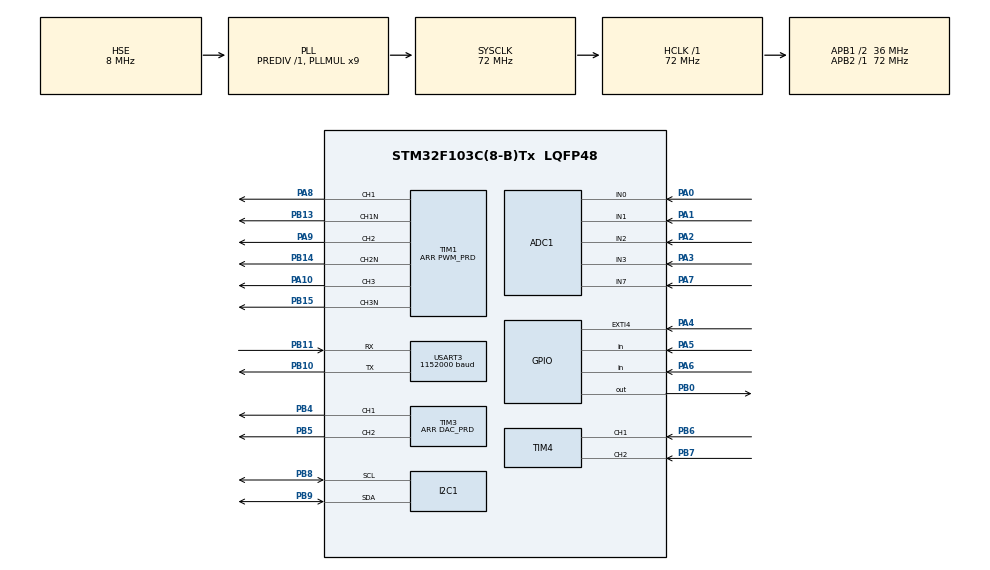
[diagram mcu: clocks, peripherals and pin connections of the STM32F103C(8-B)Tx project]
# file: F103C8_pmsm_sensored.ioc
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ADC1.Channel-10\#ChannelInjectedConversion=ADC_CHANNEL_3
ADC1.Channel-11\#ChannelInjectedConversion=ADC_CHANNEL_0
ADC1.Channel-12\#ChannelRegularConversion=ADC_CHANNEL_7
ADC1.Channel-8\#ChannelInjectedConversion=ADC_CHANNEL_1
ADC1.Channel-9\#ChannelInjectedConversion=ADC_CHANNEL_2
ADC1.ContinuousConvMode=DISABLE
ADC1.DataAlign=ADC_DATAALIGN_RIGHT
ADC1.DiscontinuousConvMode=DISABLE
ADC1.EnableAnalogWatchDog=false
ADC1.EnableRegularConversion=ENABLE
ADC1.ExternalTrigInjecConv=ADC_EXTERNALTRIGINJECCONV_T1_CC4
ADC1.InjNumberOfConversion=4
ADC1.InjectedConvMode=None
ADC1.InjectedOffset-10\#ChannelInjectedConversion=0
ADC1.InjectedOffset-11\#ChannelInjectedConversion=0
ADC1.InjectedOffset-8\#ChannelInjectedConversion=0
ADC1.InjectedOffset-9\#ChannelInjectedConversion=0
ADC1.NbrOfConversionFlag=1
ADC1.Rank-10\#ChannelInjectedConversion=3
ADC1.Rank-11\#ChannelInjectedConversion=4
ADC1.Rank-12\#ChannelRegularConversion=1
ADC1.Rank-8\#ChannelInjectedConversion=1
ADC1.Rank-9\#ChannelInjectedConversion=2
ADC1.SamplingTime-10\#ChannelInjectedConversion=ADC_SAMPLETIME_1CYCLE_5
ADC1.SamplingTime-11\#ChannelInjectedConversion=ADC_SAMPLETIME_1CYCLE_5
ADC1.SamplingTime-12\#ChannelRegularConversion=ADC_SAMPLETIME_1CYCLE_5
ADC1.SamplingTime-8\#ChannelInjectedConversion=ADC_SAMPLETIME_1CYCLE_5
ADC1.SamplingTime-9\#ChannelInjectedConversion=ADC_SAMPLETIME_1CYCLE_5
ADC1.ScanConvMode=ADC_SCAN_ENABLE
ADC1.master=1
Dma.ADC1.0.Direction=DMA_PERIPH_TO_MEMORY
Dma.ADC1.0.Instance=DMA1_Channel1
Dma.ADC1.0.MemDataAlignment=DMA_MDATAALIGN_WORD
Dma.ADC1.0.MemInc=DMA_MINC_ENABLE
Dma.ADC1.0.Mode=DMA_CIRCULAR
Dma.ADC1.0.PeriphDataAlignment=DMA_PDATAALIGN_WORD
Dma.ADC1.0.PeriphInc=DMA_PINC_DISABLE
Dma.ADC1.0.Priority=DMA_PRIORITY_LOW
Dma.Request0=ADC1
Dma.Request1=USART3_RX
Dma.Request2=USART3_TX
Dma.USART3_RX.1.Direction=DMA_PERIPH_TO_MEMORY
Dma.USART3_RX.1.Instance=DMA1_Channel3
Dma.USART3_RX.1.MemDataAlignment=DMA_MDATAALIGN_BYTE
Dma.USART3_RX.1.MemInc=DMA_MINC_ENABLE
Dma.USART3_RX.1.Mode=DMA_NORMAL
Dma.USART3_RX.1.PeriphDataAlignment=DMA_PDATAALIGN_BYTE
Dma.USART3_RX.1.PeriphInc=DMA_PINC_DISABLE
Dma.USART3_RX.1.Priority=DMA_PRIORITY_LOW
Dma.USART3_TX.2.Direction=DMA_MEMORY_TO_PERIPH
Dma.USART3_TX.2.Instance=DMA1_Channel2
Dma.USART3_TX.2.MemDataAlignment=DMA_MDATAALIGN_BYTE
Dma.USART3_TX.2.MemInc=DMA_MINC_ENABLE
Dma.USART3_TX.2.Mode=DMA_NORMAL
Dma.USART3_TX.2.PeriphDataAlignment=DMA_PDATAALIGN_BYTE
Dma.USART3_TX.2.PeriphInc=DMA_PINC_DISABLE
Dma.USART3_TX.2.Priority=DMA_PRIORITY_LOW
Mcu.Family=STM32F1
Mcu.Name=STM32F103C(8-B)Tx
Mcu.Package=LQFP48
Mcu.UserConstants=PWM_PRD,72000000/pwmFreq/2;DAC_PRD,1024;pwmFreq,10000;Uart3BaudRate,1152000
NVIC.ADC1_2_IRQn=true\:0\:0\:false\:false\:true
NVIC.DMA1_Channel1_IRQn=true\:0\:0\:false\:false\:true
NVIC.DMA1_Channel2_IRQn=true\:0\:0\:false\:false\:true
NVIC.DMA1_Channel3_IRQn=true\:0\:0\:false\:false\:true
NVIC.EXTI4_IRQn=true\:0\:0\:false\:false\:true
NVIC.PriorityGroup=NVIC_PRIORITYGROUP_4
NVIC.TIM1_CC_IRQn=true\:0\:0\:false\:false\:true
NVIC.TIM1_UP_IRQn=true\:1\:0\:true\:false\:true
NVIC.TIM3_IRQn=true\:0\:0\:false\:false\:true
NVIC.USART3_IRQn=true\:0\:0\:false\:false\:true
PA0-WKUP.Signal=ADCx_IN0
PA1.Signal=ADCx_IN1
PA10.Signal=S_TIM1_CH3
PA13.Mode=Serial_Wire
PA13.Signal=SYS_JTMS-SWDIO
PA14.Mode=Serial_Wire
PA14.Signal=SYS_JTCK-SWCLK
PA2.Signal=ADCx_IN2
PA3.Signal=ADCx_IN3
PA4.GPIO_ModeDefaultEXTI=GPIO_MODE_IT_RISING_FALLING
PA4.GPIO_PuPd=GPIO_PULLUP
PA4.Signal=GPXTI4
PA5.GPIO_PuPd=GPIO_PULLUP
PA5.Signal=GPIO_Input
PA6.GPIO_PuPd=GPIO_PULLUP
PA6.Signal=GPIO_Input
PA7.Signal=ADCx_IN7
PA8.Signal=S_TIM1_CH1
PA9.Signal=S_TIM1_CH2
PB0.Signal=GPIO_Output
PB10.Mode=Asynchronous
PB10.Signal=USART3_TX
PB11.Mode=Asynchronous
PB11.Signal=USART3_RX
PB13.Mode=PWM Generation1 CH1 CH1N
PB13.Signal=TIM1_CH1N
PB14.Mode=PWM Generation2 CH2 CH2N
PB14.Signal=TIM1_CH2N
PB15.Mode=PWM Generation3 CH3 CH3N
PB15.Signal=TIM1_CH3N
PB4.Signal=S_TIM3_CH1
PB5.Signal=S_TIM3_CH2
PB6.GPIO_PuPd=GPIO_PULLUP
PB6.Signal=S_TIM4_CH1
PB7.GPIO_PuPd=GPIO_PULLUP
PB7.Signal=S_TIM4_CH2
PB8.Mode=I2C
PB8.Signal=I2C1_SCL
PB9.Mode=I2C
PB9.Signal=I2C1_SDA
PC14-OSC32_IN.Mode=LSE-External-Oscillator
PC14-OSC32_IN.Signal=RCC_OSC32_IN
PC15-OSC32_OUT.Mode=LSE-External-Oscillator
PC15-OSC32_OUT.Signal=RCC_OSC32_OUT
PD0-OSC_IN.Mode=HSE-External-Oscillator
PD0-OSC_IN.Signal=RCC_OSC_IN
PD1-OSC_OUT.Mode=HSE-External-Oscillator
PD1-OSC_OUT.Signal=RCC_OSC_OUT
ProjectManager.HeapSize=0x200
ProjectManager.StackSize=0x400
ProjectManager.TargetToolchain=SW4STM32
RCC.ADCPresc=RCC_ADCPCLK2_DIV6
RCC.AHBFreq_Value=72000000
RCC.APB1CLKDivider=RCC_HCLK_DIV2
RCC.APB1Freq_Value=36000000
RCC.APB1TimFreq_Value=72000000
RCC.APB2Freq_Value=72000000
RCC.APB2TimFreq_Value=72000000
RCC.HCLKFreq_Value=72000000
RCC.PLLMUL=RCC_PLL_MUL9
RCC.PLLSourceVirtual=RCC_PLLSOURCE_HSE
RCC.SYSCLKFreq_VALUE=72000000
RCC.SYSCLKSource=RCC_SYSCLKSOURCE_PLLCLK
RCC.USBFreq_Value=48000000
RCC.USBPrescaler=RCC_USBCLKSOURCE_PLL_DIV1_5
SH.ADCx_IN0.0=ADC1_IN0,IN0
SH.ADCx_IN1.0=ADC1_IN1,IN1
SH.ADCx_IN2.0=ADC1_IN2,IN2
SH.ADCx_IN3.0=ADC1_IN3,IN3
SH.ADCx_IN7.0=ADC1_IN7,IN7
SH.S_TIM1_CH1.0=TIM1_CH1,PWM Generation1 CH1 CH1N
SH.S_TIM1_CH2.0=TIM1_CH2,PWM Generation2 CH2 CH2N
SH.S_TIM1_CH3.0=TIM1_CH3,PWM Generation3 CH3 CH3N
SH.S_TIM3_CH1.0=TIM3_CH1,PWM Generation1 CH1
SH.S_TIM3_CH2.0=TIM3_CH2,PWM Generation2 CH2
SH.S_TIM4_CH1.0=TIM4_CH1,Encoder_Interface
SH.S_TIM4_CH2.0=TIM4_CH2,Encoder_Interface
TIM1.AutomaticOutput=TIM_AUTOMATICOUTPUT_DISABLE
TIM1.BreakState=TIM_BREAK_DISABLE
TIM1.Channel-PWM\ Generation1\ CH1\ CH1N=TIM_CHANNEL_1
TIM1.Channel-PWM\ Generation2\ CH2\ CH2N=TIM_CHANNEL_2
TIM1.Channel-PWM\ Generation3\ CH3\ CH3N=TIM_CHANNEL_3
TIM1.Channel-PWM\ Generation4\ No\ Output=TIM_CHANNEL_4
TIM1.ClockDivision=TIM_CLOCKDIVISION_DIV1
TIM1.CounterMode=TIM_COUNTERMODE_CENTERALIGNED1
TIM1.DeadTime=50
TIM1.LockLevel=TIM_LOCKLEVEL_OFF
TIM1.OCFastMode_PWM-PWM\ Generation1\ CH1\ CH1N=TIM_OCFAST_ENABLE
TIM1.OCFastMode_PWM-PWM\ Generation2\ CH2\ CH2N=TIM_OCFAST_ENABLE
TIM1.OCFastMode_PWM-PWM\ Generation3\ CH3\ CH3N=TIM_OCFAST_ENABLE
TIM1.OCFastMode_PWM-PWM\ Generation4\ No\ Output=TIM_OCFAST_ENABLE
TIM1.OCMode_PWM-PWM\ Generation1\ CH1\ CH1N=TIM_OCMODE_PWM2
TIM1.OCMode_PWM-PWM\ Generation2\ CH2\ CH2N=TIM_OCMODE_PWM2
TIM1.OCMode_PWM-PWM\ Generation3\ CH3\ CH3N=TIM_OCMODE_PWM2
TIM1.OCMode_PWM-PWM\ Generation4\ No\ Output=TIM_OCMODE_PWM1
TIM1.OffStateIDLEMode=TIM_OSSI_DISABLE
TIM1.OffStateRunMode=TIM_OSSR_ENABLE
TIM1.Period=PWM_PRD
TIM1.Pulse-PWM\ Generation1\ CH1\ CH1N=0
TIM1.Pulse-PWM\ Generation2\ CH2\ CH2N=0
TIM1.Pulse-PWM\ Generation3\ CH3\ CH3N=0
TIM1.RepetitionCounter=1
TIM1.TIM_MasterOutputTrigger=TIM_TRGO_ENABLE
TIM1.TIM_MasterSlaveMode=TIM_MASTERSLAVEMODE_DISABLE
TIM3.Channel-PWM\ Generation1\ CH1=TIM_CHANNEL_1
TIM3.Channel-PWM\ Generation2\ CH2=TIM_CHANNEL_2
TIM3.OCFastMode_PWM-PWM\ Generation1\ CH1=TIM_OCFAST_ENABLE
TIM3.OCFastMode_PWM-PWM\ Generation2\ CH2=TIM_OCFAST_ENABLE
TIM3.Period=DAC_PRD
TIM4.EncoderMode=TIM_ENCODERMODE_TI12
TIM4.IC1Filter=5
TIM4.IC2Filter=5
USART3.BaudRate=1152000
USART3.VirtualMode=VM_ASYNC
VP_TIM1_VS_ClockSourceINT.Mode=Internal
VP_TIM1_VS_no_output4.Mode=PWM Generation4 No Output
VP_TIM3_VS_ClockSourceINT.Mode=Internal
board=F103C8_pmsm_sensored

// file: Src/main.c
/**
  ******************************************************************************
  * File Name          : main.c
  * Description        : Main program body
  ******************************************************************************
  ** This notice applies to any and all portions of this file
  * that are not between comment pairs USER CODE BEGIN and
  * USER CODE END. Other portions of this file, whether
  * inserted by the user or by software development tools
  * are owned by their respective copyright owners.
  *
  * COPYRIGHT(c) 2017 STMicroelectronics
  *
  * Redistribution and use in source and binary forms, with or without modification,
  * are permitted provided that the following conditions are met:
  *   1. Redistributions of source code must retain the above copyright notice,
  *      this list of conditions and the following disclaimer.
  *   2. Redistributions in binary form must reproduce the above copyright notice,
  *      this list of conditions and the following disclaimer in the documentation
  *      and/or other materials provided with the distribution.
  *   3. Neither the name of STMicroelectronics nor the names of its contributors
  *      may be used to endorse or promote products derived from this software
  *      without specific prior written permission.
  *
  * THIS SOFTWARE IS PROVIDED BY THE COPYRIGHT HOLDERS AND CONTRIBUTORS "AS IS"
  * AND ANY EXPRESS OR IMPLIED WARRANTIES, INCLUDING, BUT NOT LIMITED TO, THE
  * IMPLIED WARRANTIES OF MERCHANTABILITY AND FITNESS FOR A PARTICULAR PURPOSE ARE
  * DISCLAIMED. IN NO EVENT SHALL THE COPYRIGHT HOLDER OR CONTRIBUTORS BE LIABLE
  * FOR ANY DIRECT, INDIRECT, INCIDENTAL, SPECIAL, EXEMPLARY, OR CONSEQUENTIAL
  * DAMAGES (INCLUDING, BUT NOT LIMITED TO, PROCUREMENT OF SUBSTITUTE GOODS OR
  * SERVICES; LOSS OF USE, DATA, OR PROFITS; OR BUSINESS INTERRUPTION) HOWEVER
  * CAUSED AND ON ANY THEORY OF LIABILITY, WHETHER IN CONTRACT, STRICT LIABILITY,
  * OR TORT (INCLUDING NEGLIGENCE OR OTHERWISE) ARISING IN ANY WAY OUT OF THE USE
  * OF THIS SOFTWARE, EVEN IF ADVISED OF THE POSSIBILITY OF SUCH DAMAGE.
  *
  ******************************************************************************
  */
#include "main.h"
#include "stm32f1xx_hal.h"

/* USER CODE BEGIN Includes */
#include "mainmain.h"
/* USER CODE END Includes */

ADC_HandleTypeDef hadc1;
DMA_HandleTypeDef hdma_adc1;

I2C_HandleTypeDef hi2c1;

TIM_HandleTypeDef htim1;
TIM_HandleTypeDef htim3;
TIM_HandleTypeDef htim4;

UART_HandleTypeDef huart3;
DMA_HandleTypeDef hdma_usart3_rx;
DMA_HandleTypeDef hdma_usart3_tx;

/* USER CODE BEGIN PV */
/* Private variables ---------------------------------------------------------*/

/* USER CODE END PV */

void SystemClock_Config(void);
static void MX_GPIO_Init(void);
static void MX_DMA_Init(void);
static void MX_TIM1_Init(void);
static void MX_ADC1_Init(void);
static void MX_TIM3_Init(void);
static void MX_TIM4_Init(void);
static void MX_USART3_UART_Init(void);
static void MX_I2C1_Init(void);

void HAL_TIM_MspPostInit(TIM_HandleTypeDef *htim);

/* USER CODE BEGIN PFP */
/* Private function prototypes -----------------------------------------------*/

/* USER CODE END PFP */

int main(void)
{

  /* MCU Configuration----------------------------------------------------------*/

  /* Reset of all peripherals, Initializes the Flash interface and the Systick. */
  HAL_Init();

  /* Configure the system clock */
  SystemClock_Config();

  /* Initialize all configured peripherals */
  MX_GPIO_Init();
  MX_DMA_Init();
  MX_TIM1_Init();
  MX_ADC1_Init();
  MX_TIM3_Init();
  MX_TIM4_Init();
  MX_USART3_UART_Init();
  MX_I2C1_Init();

  /* USER CODE BEGIN 2 */
	userinit();
  /* USER CODE END 2 */

  /* Infinite loop */
	while (1)
	{

  /* USER CODE BEGIN 3 */
		userloop();
	}
  /* USER CODE END 3 */

}

/** System Clock Configuration
*/
void SystemClock_Config(void)
{

  RCC_OscInitTypeDef RCC_OscInitStruct;
  RCC_ClkInitTypeDef RCC_ClkInitStruct;
  RCC_PeriphCLKInitTypeDef PeriphClkInit;

    /**Initializes the CPU, AHB and APB busses clocks
    */
  RCC_OscInitStruct.OscillatorType = RCC_OSCILLATORTYPE_HSE;
  RCC_OscInitStruct.HSEState = RCC_HSE_ON;
  RCC_OscInitStruct.HSEPredivValue = RCC_HSE_PREDIV_DIV1;
  RCC_OscInitStruct.HSIState = RCC_HSI_ON;
  RCC_OscInitStruct.PLL.PLLState = RCC_PLL_ON;
  RCC_OscInitStruct.PLL.PLLSource = RCC_PLLSOURCE_HSE;
  RCC_OscInitStruct.PLL.PLLMUL = RCC_PLL_MUL9;
  if (HAL_RCC_OscConfig(&RCC_OscInitStruct) != HAL_OK)
  {
    _Error_Handler(__FILE__, __LINE__);
  }

    /**Initializes the CPU, AHB and APB busses clocks
    */
  RCC_ClkInitStruct.ClockType = RCC_CLOCKTYPE_HCLK|RCC_CLOCKTYPE_SYSCLK
                              |RCC_CLOCKTYPE_PCLK1|RCC_CLOCKTYPE_PCLK2;
  RCC_ClkInitStruct.SYSCLKSource = RCC_SYSCLKSOURCE_PLLCLK;
  RCC_ClkInitStruct.AHBCLKDivider = RCC_SYSCLK_DIV1;
  RCC_ClkInitStruct.APB1CLKDivider = RCC_HCLK_DIV2;
  RCC_ClkInitStruct.APB2CLKDivider = RCC_HCLK_DIV1;

  if (HAL_RCC_ClockConfig(&RCC_ClkInitStruct, FLASH_LATENCY_2) != HAL_OK)
  {
    _Error_Handler(__FILE__, __LINE__);
  }

  PeriphClkInit.PeriphClockSelection = RCC_PERIPHCLK_ADC;
  PeriphClkInit.AdcClockSelection = RCC_ADCPCLK2_DIV6;
  if (HAL_RCCEx_PeriphCLKConfig(&PeriphClkInit) != HAL_OK)
  {
    _Error_Handler(__FILE__, __LINE__);
  }

    /**Configure the Systick interrupt time
    */
  HAL_SYSTICK_Config(HAL_RCC_GetHCLKFreq()/1000);

    /**Configure the Systick
    */
  HAL_SYSTICK_CLKSourceConfig(SYSTICK_CLKSOURCE_HCLK);

  /* SysTick_IRQn interrupt configuration */
  HAL_NVIC_SetPriority(SysTick_IRQn, 0, 0);
}

/* ADC1 init function */
static void MX_ADC1_Init(void)
{

  ADC_InjectionConfTypeDef sConfigInjected;
  ADC_ChannelConfTypeDef sConfig;

    /**Common config
    */
  hadc1.Instance = ADC1;
  hadc1.Init.ScanConvMode = ADC_SCAN_ENABLE;
  hadc1.Init.ContinuousConvMode = DISABLE;
  hadc1.Init.DiscontinuousConvMode = DISABLE;
  hadc1.Init.ExternalTrigConv = ADC_SOFTWARE_START;
  hadc1.Init.DataAlign = ADC_DATAALIGN_RIGHT;
  hadc1.Init.NbrOfConversion = 1;
  if (HAL_ADC_Init(&hadc1) != HAL_OK)
  {
    _Error_Handler(__FILE__, __LINE__);
  }

    /**Configure Injected Channel
    */
  sConfigInjected.InjectedChannel = ADC_CHANNEL_1;
  sConfigInjected.InjectedRank = 1;
  sConfigInjected.InjectedNbrOfConversion = 4;
  sConfigInjected.InjectedSamplingTime = ADC_SAMPLETIME_1CYCLE_5;
  sConfigInjected.ExternalTrigInjecConv = ADC_EXTERNALTRIGINJECCONV_T1_CC4;
  sConfigInjected.AutoInjectedConv = DISABLE;
  sConfigInjected.InjectedDiscontinuousConvMode = DISABLE;
  sConfigInjected.InjectedOffset = 0;
  if (HAL_ADCEx_InjectedConfigChannel(&hadc1, &sConfigInjected) != HAL_OK)
  {
    _Error_Handler(__FILE__, __LINE__);
  }

    /**Configure Injected Channel
    */
  sConfigInjected.InjectedChannel = ADC_CHANNEL_2;
  sConfigInjected.InjectedRank = 2;
  if (HAL_ADCEx_InjectedConfigChannel(&hadc1, &sConfigInjected) != HAL_OK)
  {
    _Error_Handler(__FILE__, __LINE__);
  }

    /**Configure Injected Channel
    */
  sConfigInjected.InjectedChannel = ADC_CHANNEL_3;
  sConfigInjected.InjectedRank = 3;
  if (HAL_ADCEx_InjectedConfigChannel(&hadc1, &sConfigInjected) != HAL_OK)
  {
    _Error_Handler(__FILE__, __LINE__);
  }

    /**Configure Injected Channel
    */
  sConfigInjected.InjectedChannel = ADC_CHANNEL_0;
  sConfigInjected.InjectedRank = 4;
  if (HAL_ADCEx_InjectedConfigChannel(&hadc1, &sConfigInjected) != HAL_OK)
  {
    _Error_Handler(__FILE__, __LINE__);
  }

    /**Configure Regular Channel
    */
  sConfig.Channel = ADC_CHANNEL_7;
  sConfig.Rank = 1;
  sConfig.SamplingTime = ADC_SAMPLETIME_1CYCLE_5;
  if (HAL_ADC_ConfigChannel(&hadc1, &sConfig) != HAL_OK)
  {
    _Error_Handler(__FILE__, __LINE__);
  }

}

/* I2C1 init function */
static void MX_I2C1_Init(void)
{

  hi2c1.Instance = I2C1;
  hi2c1.Init.ClockSpeed = 100000;
  hi2c1.Init.DutyCycle = I2C_DUTYCYCLE_2;
  hi2c1.Init.OwnAddress1 = 0;
  hi2c1.Init.AddressingMode = I2C_ADDRESSINGMODE_7BIT;
  hi2c1.Init.DualAddressMode = I2C_DUALADDRESS_DISABLE;
  hi2c1.Init.OwnAddress2 = 0;
  hi2c1.Init.GeneralCallMode = I2C_GENERALCALL_DISABLE;
  hi2c1.Init.NoStretchMode = I2C_NOSTRETCH_DISABLE;
  if (HAL_I2C_Init(&hi2c1) != HAL_OK)
  {
    _Error_Handler(__FILE__, __LINE__);
  }

}

/* TIM1 init function */
static void MX_TIM1_Init(void)
{

  TIM_ClockConfigTypeDef sClockSourceConfig;
  TIM_MasterConfigTypeDef sMasterConfig;
  TIM_OC_InitTypeDef sConfigOC;
  TIM_BreakDeadTimeConfigTypeDef sBreakDeadTimeConfig;

  htim1.Instance = TIM1;
  htim1.Init.Prescaler = 0;
  htim1.Init.CounterMode = TIM_COUNTERMODE_CENTERALIGNED1;
  htim1.Init.Period = PWM_PRD;
  htim1.Init.ClockDivision = TIM_CLOCKDIVISION_DIV1;
  htim1.Init.RepetitionCounter = 1;
  if (HAL_TIM_Base_Init(&htim1) != HAL_OK)
  {
    _Error_Handler(__FILE__, __LINE__);
  }

  sClockSourceConfig.ClockSource = TIM_CLOCKSOURCE_INTERNAL;
  if (HAL_TIM_ConfigClockSource(&htim1, &sClockSourceConfig) != HAL_OK)
  {
    _Error_Handler(__FILE__, __LINE__);
  }

  if (HAL_TIM_PWM_Init(&htim1) != HAL_OK)
  {
    _Error_Handler(__FILE__, __LINE__);
  }

  sMasterConfig.MasterOutputTrigger = TIM_TRGO_ENABLE;
  sMasterConfig.MasterSlaveMode = TIM_MASTERSLAVEMODE_DISABLE;
  if (HAL_TIMEx_MasterConfigSynchronization(&htim1, &sMasterConfig) != HAL_OK)
  {
    _Error_Handler(__FILE__, __LINE__);
  }

  sConfigOC.OCMode = TIM_OCMODE_PWM2;
  sConfigOC.Pulse = 0;
  sConfigOC.OCPolarity = TIM_OCPOLARITY_HIGH;
  sConfigOC.OCNPolarity = TIM_OCNPOLARITY_HIGH;
  sConfigOC.OCFastMode = TIM_OCFAST_ENABLE;
  sConfigOC.OCIdleState = TIM_OCIDLESTATE_RESET;
  sConfigOC.OCNIdleState = TIM_OCNIDLESTATE_RESET;
  if (HAL_TIM_PWM_ConfigChannel(&htim1, &sConfigOC, TIM_CHANNEL_1) != HAL_OK)
  {
    _Error_Handler(__FILE__, __LINE__);
  }

  if (HAL_TIM_PWM_ConfigChannel(&htim1, &sConfigOC, TIM_CHANNEL_2) != HAL_OK)
  {
    _Error_Handler(__FILE__, __LINE__);
  }

  if (HAL_TIM_PWM_ConfigChannel(&htim1, &sConfigOC, TIM_CHANNEL_3) != HAL_OK)
  {
    _Error_Handler(__FILE__, __LINE__);
  }

  sConfigOC.OCMode = TIM_OCMODE_PWM1;
  if (HAL_TIM_PWM_ConfigChannel(&htim1, &sConfigOC, TIM_CHANNEL_4) != HAL_OK)
  {
    _Error_Handler(__FILE__, __LINE__);
  }

  sBreakDeadTimeConfig.OffStateRunMode = TIM_OSSR_ENABLE;
  sBreakDeadTimeConfig.OffStateIDLEMode = TIM_OSSI_DISABLE;
  sBreakDeadTimeConfig.LockLevel = TIM_LOCKLEVEL_OFF;
  sBreakDeadTimeConfig.DeadTime = 50;
  sBreakDeadTimeConfig.BreakState = TIM_BREAK_DISABLE;
  sBreakDeadTimeConfig.BreakPolarity = TIM_BREAKPOLARITY_HIGH;
  sBreakDeadTimeConfig.AutomaticOutput = TIM_AUTOMATICOUTPUT_DISABLE;
  if (HAL_TIMEx_ConfigBreakDeadTime(&htim1, &sBreakDeadTimeConfig) != HAL_OK)
  {
    _Error_Handler(__FILE__, __LINE__);
  }

  HAL_TIM_MspPostInit(&htim1);

}

/* TIM3 init function */
static void MX_TIM3_Init(void)
{

  TIM_ClockConfigTypeDef sClockSourceConfig;
  TIM_MasterConfigTypeDef sMasterConfig;
  TIM_OC_InitTypeDef sConfigOC;

  htim3.Instance = TIM3;
  htim3.Init.Prescaler = 0;
  htim3.Init.CounterMode = TIM_COUNTERMODE_UP;
  htim3.Init.Period = DAC_PRD;
  htim3.Init.ClockDivision = TIM_CLOCKDIVISION_DIV1;
  if (HAL_TIM_Base_Init(&htim3) != HAL_OK)
  {
    _Error_Handler(__FILE__, __LINE__);
  }

  sClockSourceConfig.ClockSource = TIM_CLOCKSOURCE_INTERNAL;
  if (HAL_TIM_ConfigClockSource(&htim3, &sClockSourceConfig) != HAL_OK)
  {
    _Error_Handler(__FILE__, __LINE__);
  }

  if (HAL_TIM_PWM_Init(&htim3) != HAL_OK)
  {
    _Error_Handler(__FILE__, __LINE__);
  }

  sMasterConfig.MasterOutputTrigger = TIM_TRGO_RESET;
  sMasterConfig.MasterSlaveMode = TIM_MASTERSLAVEMODE_DISABLE;
  if (HAL_TIMEx_MasterConfigSynchronization(&htim3, &sMasterConfig) != HAL_OK)
  {
    _Error_Handler(__FILE__, __LINE__);
  }

  sConfigOC.OCMode = TIM_OCMODE_PWM1;
  sConfigOC.Pulse = 0;
  sConfigOC.OCPolarity = TIM_OCPOLARITY_HIGH;
  sConfigOC.OCFastMode = TIM_OCFAST_ENABLE;
  if (HAL_TIM_PWM_ConfigChannel(&htim3, &sConfigOC, TIM_CHANNEL_1) != HAL_OK)
  {
    _Error_Handler(__FILE__, __LINE__);
  }

  if (HAL_TIM_PWM_ConfigChannel(&htim3, &sConfigOC, TIM_CHANNEL_2) != HAL_OK)
  {
    _Error_Handler(__FILE__, __LINE__);
  }

  HAL_TIM_MspPostInit(&htim3);

}

/* TIM4 init function */
static void MX_TIM4_Init(void)
{

  TIM_Encoder_InitTypeDef sConfig;
  TIM_MasterConfigTypeDef sMasterConfig;

  htim4.Instance = TIM4;
  htim4.Init.Prescaler = 0;
  htim4.Init.CounterMode = TIM_COUNTERMODE_UP;
  htim4.Init.Period = 0;
  htim4.Init.ClockDivision = TIM_CLOCKDIVISION_DIV1;
  sConfig.EncoderMode = TIM_ENCODERMODE_TI12;
  sConfig.IC1Polarity = TIM_ICPOLARITY_RISING;
  sConfig.IC1Selection = TIM_ICSELECTION_DIRECTTI;
  sConfig.IC1Prescaler = TIM_ICPSC_DIV1;
  sConfig.IC1Filter = 5;
  sConfig.IC2Polarity = TIM_ICPOLARITY_RISING;
  sConfig.IC2Selection = TIM_ICSELECTION_DIRECTTI;
  sConfig.IC2Prescaler = TIM_ICPSC_DIV1;
  sConfig.IC2Filter = 5;
  if (HAL_TIM_Encoder_Init(&htim4, &sConfig) != HAL_OK)
  {
    _Error_Handler(__FILE__, __LINE__);
  }

  sMasterConfig.MasterOutputTrigger = TIM_TRGO_RESET;
  sMasterConfig.MasterSlaveMode = TIM_MASTERSLAVEMODE_DISABLE;
  if (HAL_TIMEx_MasterConfigSynchronization(&htim4, &sMasterConfig) != HAL_OK)
  {
    _Error_Handler(__FILE__, __LINE__);
  }

}

/* USART3 init function */
static void MX_USART3_UART_Init(void)
{

  huart3.Instance = USART3;
  huart3.Init.BaudRate = 1152000;
  huart3.Init.WordLength = UART_WORDLENGTH_8B;
  huart3.Init.StopBits = UART_STOPBITS_1;
  huart3.Init.Parity = UART_PARITY_NONE;
  huart3.Init.Mode = UART_MODE_TX_RX;
  huart3.Init.HwFlowCtl = UART_HWCONTROL_NONE;
  huart3.Init.OverSampling = UART_OVERSAMPLING_16;
  if (HAL_UART_Init(&huart3) != HAL_OK)
  {
    _Error_Handler(__FILE__, __LINE__);
  }

}

static void MX_DMA_Init(void)
{
  /* DMA controller clock enable */
  __HAL_RCC_DMA1_CLK_ENABLE();

  /* DMA interrupt init */
  /* DMA1_Channel1_IRQn interrupt configuration */
  HAL_NVIC_SetPriority(DMA1_Channel1_IRQn, 0, 0);
  HAL_NVIC_EnableIRQ(DMA1_Channel1_IRQn);
  /* DMA1_Channel2_IRQn interrupt configuration */
  HAL_NVIC_SetPriority(DMA1_Channel2_IRQn, 0, 0);
  HAL_NVIC_EnableIRQ(DMA1_Channel2_IRQn);
  /* DMA1_Channel3_IRQn interrupt configuration */
  HAL_NVIC_SetPriority(DMA1_Channel3_IRQn, 0, 0);
  HAL_NVIC_EnableIRQ(DMA1_Channel3_IRQn);

}

/** Configure pins as
        * Analog
        * Input
        * Output
        * EVENT_OUT
        * EXTI
*/
static void MX_GPIO_Init(void)
{

  GPIO_InitTypeDef GPIO_InitStruct;

  /* GPIO Ports Clock Enable */
  __HAL_RCC_GPIOC_CLK_ENABLE();
  __HAL_RCC_GPIOD_CLK_ENABLE();
  __HAL_RCC_GPIOA_CLK_ENABLE();
  __HAL_RCC_GPIOB_CLK_ENABLE();

  /*Configure GPIO pin Output Level */
  HAL_GPIO_WritePin(GPIOB, GPIO_PIN_0, GPIO_PIN_RESET);

  /*Configure GPIO pin : PA4 */
  GPIO_InitStruct.Pin = GPIO_PIN_4;
  GPIO_InitStruct.Mode = GPIO_MODE_IT_RISING_FALLING;
  GPIO_InitStruct.Pull = GPIO_PULLUP;
  HAL_GPIO_Init(GPIOA, &GPIO_InitStruct);

  /*Configure GPIO pins : PA5 PA6 */
  GPIO_InitStruct.Pin = GPIO_PIN_5|GPIO_PIN_6;
  GPIO_InitStruct.Mode = GPIO_MODE_INPUT;
  GPIO_InitStruct.Pull = GPIO_PULLUP;
  HAL_GPIO_Init(GPIOA, &GPIO_InitStruct);

  /*Configure GPIO pin : PB0 */
  GPIO_InitStruct.Pin = GPIO_PIN_0;
  GPIO_InitStruct.Mode = GPIO_MODE_OUTPUT_PP;
  GPIO_InitStruct.Speed = GPIO_SPEED_FREQ_LOW;
  HAL_GPIO_Init(GPIOB, &GPIO_InitStruct);

  /* EXTI interrupt init*/
  HAL_NVIC_SetPriority(EXTI4_IRQn, 0, 0);
  HAL_NVIC_EnableIRQ(EXTI4_IRQn);

}

void _Error_Handler(char * file, int line)
{
	while (1)
	{
	}
}

/************************ (C) COPYRIGHT STMicroelectronics *****END OF FILE****/
